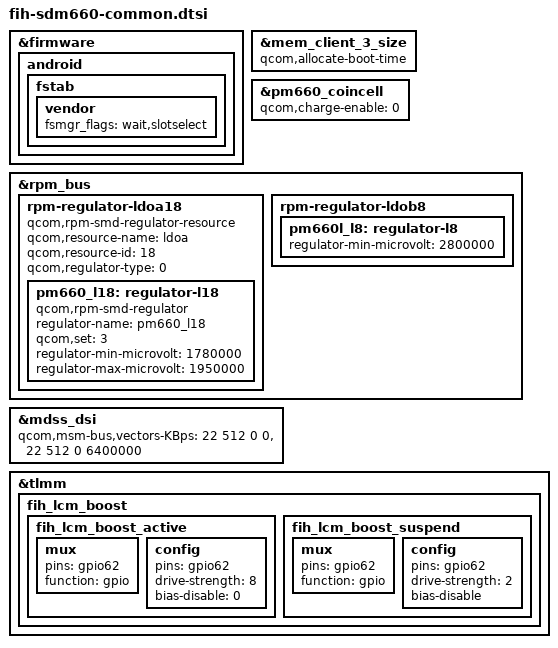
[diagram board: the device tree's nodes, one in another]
&firmware {
    android {
        fstab {
            vendor {
                fsmgr_flags = "wait,slotselect";
            };
        };
    };
};

&mem_client_3_size {
    /delete-property/ qcom,allocate-on-request;
    qcom,allocate-boot-time;
};


&pm660_coincell {
			qcom,charge-enable = <0>;
};

&rpm_bus {
	//SW4-HL-Display-BringUpILI7807E-00+{_20170327
	rpm-regulator-ldoa18 {
		compatible = "qcom,rpm-smd-regulator-resource";
		qcom,resource-name = "ldoa";
		qcom,resource-id = <18>;
		qcom,regulator-type = <0>;
		status = "okay";

		pm660_l18: regulator-l18 {
			compatible = "qcom,rpm-smd-regulator";
			regulator-name = "pm660_l18";
			qcom,set = <3>;
			regulator-min-microvolt = <1780000>;
			regulator-max-microvolt = <1950000>;
			status = "okay";
		};
	};
	//SW4-HL-Display-BringUpILI7807E-00+}_20170327
	rpm-regulator-ldob8 {
		pm660l_l8: regulator-l8 {
			regulator-min-microvolt = <2800000>;
		};
	};
};

&pm660l_l8 {
	regulator-min-microvolt = <2800000>;
};

&mdss_dsi {
		qcom,msm-bus,vectors-KBps =
			<22 512 0 0>,
			<22 512 0 6400000>;
};

&tlmm {
    fih_lcm_boost: fih_lcm_boost {
        fih_lcm_boost_active: fih_lcm_boost_active {
            mux {
                pins = "gpio62";
                function = "gpio";
            };

            config {
                pins = "gpio62";
                drive-strength = <8>; /* 8 mA */
                bias-disable = <0>; /* no pull */
            };
        };
        fih_lcm_boost_suspend: fih_lcm_boost_suspend {
            mux {
                pins = "gpio62";
                function = "gpio";
            };

            config {
                pins = "gpio62";
                drive-strength = <2>; /* 2 mA */
                bias-disable; /* pull down */
            };
        };
    };
};
